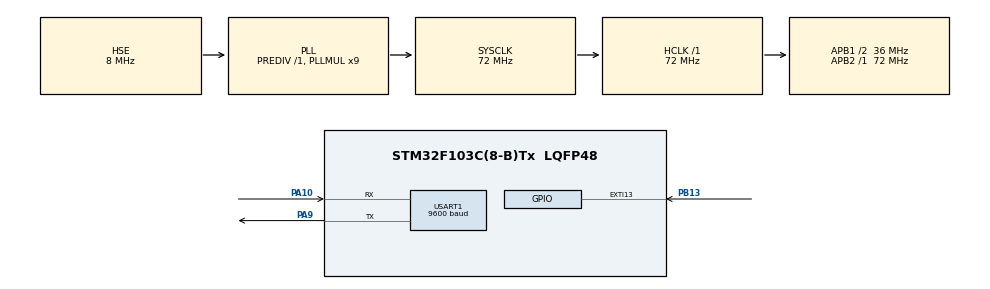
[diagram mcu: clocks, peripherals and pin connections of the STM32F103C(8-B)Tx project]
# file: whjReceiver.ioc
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Dma.Request0=USART1_TX
Dma.USART1_TX.0.Direction=DMA_MEMORY_TO_PERIPH
Dma.USART1_TX.0.Instance=DMA1_Channel4
Dma.USART1_TX.0.MemDataAlignment=DMA_MDATAALIGN_BYTE
Dma.USART1_TX.0.MemInc=DMA_MINC_ENABLE
Dma.USART1_TX.0.Mode=DMA_NORMAL
Dma.USART1_TX.0.PeriphDataAlignment=DMA_PDATAALIGN_BYTE
Dma.USART1_TX.0.PeriphInc=DMA_PINC_DISABLE
Dma.USART1_TX.0.Priority=DMA_PRIORITY_LOW
Mcu.Family=STM32F1
Mcu.Name=STM32F103C(8-B)Tx
Mcu.Package=LQFP48
NVIC.DMA1_Channel4_IRQn=true\:0\:0\:false\:false\:true\:false\:true\:true
NVIC.EXTI15_10_IRQn=true\:0\:0\:false\:false\:true\:true\:true\:true
NVIC.PriorityGroup=NVIC_PRIORITYGROUP_4
NVIC.TIM2_IRQn=true\:0\:0\:false\:false\:true\:true\:true\:true
PA10.Mode=Asynchronous
PA10.Signal=USART1_RX
PA13.Mode=Serial_Wire
PA13.Signal=SYS_JTMS-SWDIO
PA14.Mode=Serial_Wire
PA14.Signal=SYS_JTCK-SWCLK
PA9.Mode=Asynchronous
PA9.Signal=USART1_TX
PB13.GPIO_ModeDefaultEXTI=GPIO_MODE_IT_FALLING
PB13.GPIO_PuPd=GPIO_PULLUP
PB13.Signal=GPXTI13
PD0-OSC_IN.Mode=HSE-External-Oscillator
PD0-OSC_IN.Signal=RCC_OSC_IN
PD1-OSC_OUT.Mode=HSE-External-Oscillator
PD1-OSC_OUT.Signal=RCC_OSC_OUT
ProjectManager.HeapSize=0x200
ProjectManager.StackSize=0x400
ProjectManager.TargetToolchain=MDK-ARM V5.32
RCC.AHBFreq_Value=72000000
RCC.APB1CLKDivider=RCC_HCLK_DIV2
RCC.APB1Freq_Value=36000000
RCC.APB1TimFreq_Value=72000000
RCC.APB2Freq_Value=72000000
RCC.APB2TimFreq_Value=72000000
RCC.HCLKFreq_Value=72000000
RCC.PLLMUL=RCC_PLL_MUL9
RCC.PLLSourceVirtual=RCC_PLLSOURCE_HSE
RCC.SYSCLKFreq_VALUE=72000000
RCC.SYSCLKSource=RCC_SYSCLKSOURCE_PLLCLK
RCC.USBFreq_Value=72000000
TIM2.Period=103
TIM2.Prescaler=71
USART1.BaudRate=9600
USART1.VirtualMode=VM_ASYNC
VP_TIM2_VS_ClockSourceINT.Mode=Internal
board=custom

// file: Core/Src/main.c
/* USER CODE BEGIN Header */
/**
  ******************************************************************************
  * @file           : main.c
  * @brief          : Main program body
  ******************************************************************************
  * @attention
  *
  * Copyright (c) 2025 STMicroelectronics.
  * All rights reserved.
  *
  * This software is licensed under terms that can be found in the LICENSE file
  * in the root directory of this software component.
  * If no LICENSE file comes with this software, it is provided AS-IS.
  *
  ******************************************************************************
  */
/* USER CODE END Header */
#include "main.h"

/* USER CODE BEGIN Includes */
#include <string.h>
#include <stdio.h>
/* USER CODE END Includes */

TIM_HandleTypeDef htim2;

UART_HandleTypeDef huart1;
DMA_HandleTypeDef hdma_usart1_tx;

/* USER CODE BEGIN PV */
#define RX_GPIO_Port GPIOB
#define RX_Pin       GPIO_PIN_13
static volatile uint8_t  rxByte    = 0;
static volatile int8_t   rxIdx     = -1;
static uint32_t          bit_us    = 0;
static volatile uint8_t  byteReady = 0;

static char txbuf[16];
/* USER CODE END PV */

void SystemClock_Config(void);
static void MX_GPIO_Init(void);
static void MX_DMA_Init(void);
static void MX_USART1_UART_Init(void);
static void MX_TIM2_Init(void);
/* USER CODE BEGIN PFP */
static void RX_TimerStart(void);
static void RX_TimerStop(void);
static void RX_TimerReconfig_1MHz(uint32_t arr_us);
/* USER CODE END PFP */

/* USER CODE BEGIN 0 */
extern TIM_HandleTypeDef  htim2;
extern UART_HandleTypeDef huart1;

static void RX_TimerStart(void){ HAL_TIM_Base_Start_IT(&htim2); }
static void RX_TimerStop(void) { HAL_TIM_Base_Stop_IT(&htim2);  }

static void RX_TimerReconfig_1MHz(uint32_t arr_us)
{
  uint32_t pclk1 = HAL_RCC_GetPCLK1Freq();
  uint32_t timclk = pclk1;
  if ((RCC->CFGR & RCC_CFGR_PPRE1) != RCC_CFGR_PPRE1_DIV1) timclk *= 2U;

  uint32_t psc = (timclk / 1000000U) - 1U;   // 1MHz
  __HAL_TIM_DISABLE(&htim2);
  htim2.Instance->PSC = psc;
  htim2.Instance->ARR = (arr_us ? arr_us : 104) - 1U;
  __HAL_TIM_SET_COUNTER(&htim2, 0);
  __HAL_TIM_ENABLE(&htim2);
}

void HAL_TIM_PeriodElapsedCallback(TIM_HandleTypeDef *htim)
{
  if (htim->Instance == TIM2)
  {
    uint8_t level = (HAL_GPIO_ReadPin(RX_GPIO_Port, RX_Pin) == GPIO_PIN_SET) ? 1 : 0;

    if (rxIdx >= 0 && rxIdx <= 7)
    {
      rxByte |= (level << rxIdx);
      rxIdx++;
      htim2.Instance->ARR = bit_us - 1U;
    }
    else if (rxIdx == 8)
    {

      RX_TimerStop();
      rxIdx = -1;
      byteReady = 1;

      __HAL_GPIO_EXTI_CLEAR_IT(RX_Pin);
      HAL_NVIC_EnableIRQ(EXTI15_10_IRQn);
    }
  }
}

void HAL_UART_TxCpltCallback(UART_HandleTypeDef *huart)
{
  if (huart->Instance == USART1)
  {

  }
}
/* USER CODE END 0 */

int main(void)
{

  /* MCU Configuration--------------------------------------------------------*/

  /* Reset of all peripherals, Initializes the Flash interface and the Systick. */
  HAL_Init();

  /* Configure the system clock */
  SystemClock_Config();

  /* Initialize all configured peripherals */
  MX_GPIO_Init();
  MX_DMA_Init();
  MX_USART1_UART_Init();
  MX_TIM2_Init();
  /* USER CODE BEGIN 2 */
bit_us = (uint32_t)(1000000.0/9600.0 + 0.5);
  /* USER CODE END 2 */

  /* Infinite loop */
  /* USER CODE BEGIN WHILE */

  while (1)

  {if (byteReady)
    {
      byteReady = 0;
      int n = snprintf(txbuf, sizeof(txbuf), "%u\r\n", rxByte);
      if (n > 0)
      {
        // ?? USART1 + DMA1_Channel4 ????????
        HAL_UART_Transmit_DMA(&huart1, (uint8_t*)txbuf, (uint16_t)n);
      }
    }
    /* USER CODE END WHILE */

	}
}

void SystemClock_Config(void)
{
  RCC_OscInitTypeDef RCC_OscInitStruct = {0};
  RCC_ClkInitTypeDef RCC_ClkInitStruct = {0};

  /** Initializes the RCC Oscillators according to the specified parameters
  * in the RCC_OscInitTypeDef structure.
  */
  RCC_OscInitStruct.OscillatorType = RCC_OSCILLATORTYPE_HSE;
  RCC_OscInitStruct.HSEState = RCC_HSE_ON;
  RCC_OscInitStruct.HSEPredivValue = RCC_HSE_PREDIV_DIV1;
  RCC_OscInitStruct.HSIState = RCC_HSI_ON;
  RCC_OscInitStruct.PLL.PLLState = RCC_PLL_ON;
  RCC_OscInitStruct.PLL.PLLSource = RCC_PLLSOURCE_HSE;
  RCC_OscInitStruct.PLL.PLLMUL = RCC_PLL_MUL9;
  if (HAL_RCC_OscConfig(&RCC_OscInitStruct) != HAL_OK)
  {
    Error_Handler();
  }

  /** Initializes the CPU, AHB and APB buses clocks
  */
  RCC_ClkInitStruct.ClockType = RCC_CLOCKTYPE_HCLK|RCC_CLOCKTYPE_SYSCLK
                              |RCC_CLOCKTYPE_PCLK1|RCC_CLOCKTYPE_PCLK2;
  RCC_ClkInitStruct.SYSCLKSource = RCC_SYSCLKSOURCE_PLLCLK;
  RCC_ClkInitStruct.AHBCLKDivider = RCC_SYSCLK_DIV1;
  RCC_ClkInitStruct.APB1CLKDivider = RCC_HCLK_DIV2;
  RCC_ClkInitStruct.APB2CLKDivider = RCC_HCLK_DIV1;

  if (HAL_RCC_ClockConfig(&RCC_ClkInitStruct, FLASH_LATENCY_2) != HAL_OK)
  {
    Error_Handler();
  }
}

static void MX_TIM2_Init(void)
{

  TIM_ClockConfigTypeDef sClockSourceConfig = {0};
  TIM_MasterConfigTypeDef sMasterConfig = {0};

  htim2.Instance = TIM2;
  htim2.Init.Prescaler = 71;
  htim2.Init.CounterMode = TIM_COUNTERMODE_UP;
  htim2.Init.Period = 103;
  htim2.Init.ClockDivision = TIM_CLOCKDIVISION_DIV1;
  htim2.Init.AutoReloadPreload = TIM_AUTORELOAD_PRELOAD_DISABLE;
  if (HAL_TIM_Base_Init(&htim2) != HAL_OK)
  {
    Error_Handler();
  }
  sClockSourceConfig.ClockSource = TIM_CLOCKSOURCE_INTERNAL;
  if (HAL_TIM_ConfigClockSource(&htim2, &sClockSourceConfig) != HAL_OK)
  {
    Error_Handler();
  }
  sMasterConfig.MasterOutputTrigger = TIM_TRGO_RESET;
  sMasterConfig.MasterSlaveMode = TIM_MASTERSLAVEMODE_DISABLE;
  if (HAL_TIMEx_MasterConfigSynchronization(&htim2, &sMasterConfig) != HAL_OK)
  {
    Error_Handler();
  }

}

static void MX_USART1_UART_Init(void)
{

  huart1.Instance = USART1;
  huart1.Init.BaudRate = 9600;
  huart1.Init.WordLength = UART_WORDLENGTH_8B;
  huart1.Init.StopBits = UART_STOPBITS_1;
  huart1.Init.Parity = UART_PARITY_NONE;
  huart1.Init.Mode = UART_MODE_TX_RX;
  huart1.Init.HwFlowCtl = UART_HWCONTROL_NONE;
  huart1.Init.OverSampling = UART_OVERSAMPLING_16;
  if (HAL_UART_Init(&huart1) != HAL_OK)
  {
    Error_Handler();
  }

}

static void MX_DMA_Init(void)
{

  /* DMA controller clock enable */
  __HAL_RCC_DMA1_CLK_ENABLE();

  /* DMA interrupt init */
  /* DMA1_Channel4_IRQn interrupt configuration */
  HAL_NVIC_SetPriority(DMA1_Channel4_IRQn, 0, 0);
  HAL_NVIC_EnableIRQ(DMA1_Channel4_IRQn);

}

static void MX_GPIO_Init(void)
{
  GPIO_InitTypeDef GPIO_InitStruct = {0};

  /* GPIO Ports Clock Enable */
  __HAL_RCC_GPIOD_CLK_ENABLE();
  __HAL_RCC_GPIOB_CLK_ENABLE();
  __HAL_RCC_GPIOA_CLK_ENABLE();

  /*Configure GPIO pin : PB13 */
  GPIO_InitStruct.Pin = GPIO_PIN_13;
  GPIO_InitStruct.Mode = GPIO_MODE_IT_FALLING;
  GPIO_InitStruct.Pull = GPIO_PULLUP;
  HAL_GPIO_Init(GPIOB, &GPIO_InitStruct);

  /* EXTI interrupt init*/
  HAL_NVIC_SetPriority(EXTI15_10_IRQn, 0, 0);
  HAL_NVIC_EnableIRQ(EXTI15_10_IRQn);

}

void Error_Handler(void)
{
  __disable_irq();
  while (1)
  {
  }
}
